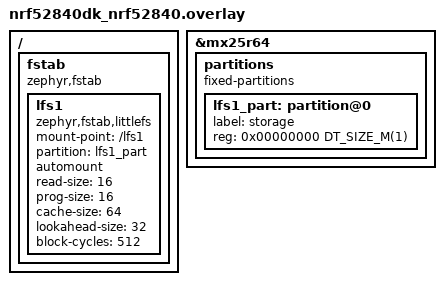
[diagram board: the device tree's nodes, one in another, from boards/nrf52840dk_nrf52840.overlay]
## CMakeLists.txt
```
# SPDX-FileCopyrightText: Copyright The Zephyr Project Contributors
# SPDX-FileCopyrightText: Copyright (c) 2026 Jeff Welder
# SPDX-License-Identifier: Apache-2.0

cmake_minimum_required(VERSION 3.20.0)
find_package(Zephyr REQUIRED HINTS $ENV{ZEPHYR_BASE})
project(smp_bt_client)

target_sources(app PRIVATE src/main.c)

# The image management client headers reach into <bootutil/image.h>, and the sample builds
# an MCUboot image header of its own, so the bootutil include path is needed here.
zephyr_library_link_libraries(MCUBOOT_BOOTUTIL)
```

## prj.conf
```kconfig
CONFIG_LOG=y
CONFIG_MAIN_STACK_SIZE=4096

# Bluetooth central with a GATT client, which is what the SMP client transport drives.
CONFIG_BT=y
CONFIG_BT_CENTRAL=y
CONFIG_BT_GATT_CLIENT=y
CONFIG_BT_DEVICE_NAME="SMP Client"

# Allow for large Bluetooth data packets, matching what smp_svr asks for in its bt.conf.
CONFIG_BT_L2CAP_TX_MTU=498
CONFIG_BT_BUF_ACL_RX_SIZE=502
CONFIG_BT_BUF_ACL_TX_SIZE=251
CONFIG_BT_CTLR_DATA_LENGTH_MAX=251

# None of the above buys anything until the ATT MTU itself is negotiated up from its
# default of 23, and only the central can ask for that: a peer running smp_svr has no GATT
# client of its own to initiate the exchange. Without this the transport spends the whole
# session writing 20 byte fragments.
CONFIG_BT_GATT_AUTO_UPDATE_MTU=y

# The client transport keeps up to MCUMGR_TRANSPORT_BT_CLIENT_TX_CREDITS write fragments in
# flight and needs an ATT buffer for each of them, with headroom left for everything else
# that shares the link.
CONFIG_BT_ATT_TX_COUNT=4

# MCUmgr SMP client over the Bluetooth central transport.
CONFIG_NET_BUF=y
CONFIG_ZCBOR=y
CONFIG_CRC=y
CONFIG_MCUMGR=y
CONFIG_SMP_CLIENT=y
CONFIG_MCUMGR_TRANSPORT_BT_CLIENT=y

# The image upload client sizes every upload frame from this without consulting the
# transport MTU, so it must not exceed the peer's own MCUMGR_TRANSPORT_NETBUF_SIZE, which
# is 2475 in the smp_svr sample.
CONFIG_MCUMGR_TRANSPORT_NETBUF_SIZE=2048

CONFIG_MCUMGR_GRP_IMG_CLIENT=y
CONFIG_MCUMGR_GRP_OS_CLIENT=y

# The image management client headers pull in <bootutil/image.h>, and the sample writes an
# MCUboot image header into the placeholder image it creates.
CONFIG_MCUBOOT_BOOTUTIL_LIB=y

# The image to upload is read from a littlefs file system.
CONFIG_FLASH=y
CONFIG_FLASH_MAP=y
CONFIG_FILE_SYSTEM=y
CONFIG_FILE_SYSTEM_LITTLEFS=y
```

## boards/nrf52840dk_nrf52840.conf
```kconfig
# The littlefs mount point is on the external QSPI flash.
CONFIG_MPU_ALLOW_FLASH_WRITE=y

# littlefs derives its block size from the flash page layout, and the default QSPI page
# size of 64 KiB would leave the 1 MiB partition with too few blocks to be usable.
CONFIG_NORDIC_QSPI_NOR_FLASH_LAYOUT_PAGE_SIZE=4096
```

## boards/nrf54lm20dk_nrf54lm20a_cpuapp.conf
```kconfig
# The littlefs mount point is on the external SPI flash rather than on a QSPI one.
CONFIG_SPI=y
CONFIG_SPI_NOR=y

# The devicetree node carries a JESD216 basic flash parameters table, so read the flash
# parameters from there instead of synthesising a minimal fixed configuration.
CONFIG_SPI_NOR_SFDP_DEVICETREE=y

# littlefs derives its block size from the flash page layout, and the driver's default
# page size of 64 KiB would leave the 1 MiB partition with too few blocks to be usable.
CONFIG_SPI_NOR_FLASH_LAYOUT_PAGE_SIZE=4096
```

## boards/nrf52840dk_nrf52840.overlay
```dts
/*
 * SPDX-FileCopyrightText: Copyright The Zephyr Project Contributors
 * SPDX-FileCopyrightText: Copyright (c) 2026 Jeff Welder
 *
 * SPDX-License-Identifier: Apache-2.0
 */

#include <zephyr/dt-bindings/dt-util.h>

/* The image to upload lives on the external QSPI flash, not in the internal one. */
/delete-node/ &storage_partition;

/ {
	fstab {
		compatible = "zephyr,fstab";

		lfs1: lfs1 {
			compatible = "zephyr,fstab,littlefs";
			mount-point = "/lfs1";
			partition = <&lfs1_part>;
			automount;
			read-size = <16>;
			prog-size = <16>;
			cache-size = <64>;
			lookahead-size = <32>;
			block-cycles = <512>;
		};
	};
};

&mx25r64 {
	partitions {
		compatible = "fixed-partitions";
		#address-cells = <1>;
		#size-cells = <1>;

		lfs1_part: partition@0 {
			label = "storage";
			reg = <0x00000000 DT_SIZE_M(1)>;
		};
	};
};
```

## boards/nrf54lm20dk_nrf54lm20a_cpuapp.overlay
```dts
/*
 * SPDX-FileCopyrightText: Copyright The Zephyr Project Contributors
 * SPDX-FileCopyrightText: Copyright (c) 2026 Jeff Welder
 *
 * SPDX-License-Identifier: Apache-2.0
 */

#include <zephyr/dt-bindings/dt-util.h>

/* The image to upload lives on the external SPI flash, not in the internal one. */
/delete-node/ &storage_partition;

/ {
	fstab {
		compatible = "zephyr,fstab";

		lfs1: lfs1 {
			compatible = "zephyr,fstab,littlefs";
			mount-point = "/lfs1";
			partition = <&lfs1_part>;
			automount;
			read-size = <16>;
			prog-size = <16>;
			cache-size = <64>;
			lookahead-size = <32>;
			block-cycles = <512>;
		};
	};
};

/*
 * The board carries the same MX25R64 as the nrf52840dk does, but on a plain SPI bus
 * rather than on QSPI, and left disabled by the board devicetree.
 */
&mx25r64 {
	status = "okay";

	partitions {
		compatible = "fixed-partitions";
		#address-cells = <1>;
		#size-cells = <1>;

		lfs1_part: partition@0 {
			label = "storage";
			reg = <0x00000000 DT_SIZE_M(1)>;
		};
	};
};
```

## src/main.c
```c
/*
 * SPDX-FileCopyrightText: Copyright The Zephyr Project Contributors
 * SPDX-FileCopyrightText: Copyright (c) 2026 Jeff Welder
 *
 * SPDX-License-Identifier: Apache-2.0
 */

/*
 * Uploads a firmware image to a Bluetooth peer that runs the SMP service, with this board
 * in the central role. The image is read from a littlefs file system on the board's
 * external QSPI flash, so nothing about it is baked into this binary.
 */

#include <errno.h>
#include <stdint.h>
#include <string.h>

#include <zephyr/bluetooth/bluetooth.h>
#include <zephyr/bluetooth/conn.h>
#include <zephyr/bluetooth/hci.h>
#include <zephyr/fs/fs.h>
#include <zephyr/kernel.h>
#include <zephyr/logging/log.h>
#include <zephyr/mgmt/mcumgr/grp/img_mgmt/img_mgmt_client.h>
#include <zephyr/mgmt/mcumgr/grp/os_mgmt/os_mgmt_client.h>
#include <zephyr/mgmt/mcumgr/smp/smp_client.h>
#include <zephyr/mgmt/mcumgr/transport/smp.h>
#include <zephyr/mgmt/mcumgr/transport/smp_bt.h>
#include <zephyr/mgmt/mcumgr/transport/smp_bt_client.h>
#include <zephyr/sys/atomic.h>

#include <bootutil/image.h>

LOG_MODULE_REGISTER(smp_bt_client_sample, LOG_LEVEL_INF);

#define AUTOMOUNT_NODE DT_NODELABEL(lfs1)
#define MOUNT_POINT    DT_PROP(AUTOMOUNT_NODE, mount_point)
#define IMAGE_PATH     MOUNT_POINT "/update.bin"

/* Placeholder image written when the file system holds no image yet. */
#define PLACEHOLDER_SIZE 4096U
/* How much of the file is handed to the image client per call. */
#define CHUNK_SIZE       1024U

#define ECHO_STRING "smp client"

BUILD_ASSERT(PLACEHOLDER_SIZE % CHUNK_SIZE == 0, "Placeholder must be a whole number of chunks");

static struct smp_client_object smp_client;
static struct img_mgmt_client img_client;
static struct os_mgmt_client os_client;
static uint8_t chunk[CHUNK_SIZE];

/*
 * The one reference this sample holds on the peer. Both the connected callback, on a
 * failed connection, and main, when it gives up waiting, want to release it, so whoever
 * swaps the pointer out first owns the release and the other side finds nothing to do.
 */
static atomic_ptr_t peer;
static K_SEM_DEFINE(peer_connected, 0, 1);

/* Matches the SMP service UUID that every Zephyr SMP Bluetooth server advertises. */
static bool adv_data_cb(struct bt_data *data, void *user_data)
{
	static const uint8_t smp_svc_uuid[] = {SMP_BT_SVC_UUID_VAL};
	bool *found = user_data;

	if (data->type == BT_DATA_UUID128_ALL && data->data_len == sizeof(smp_svc_uuid) &&
	    memcmp(data->data, smp_svc_uuid, sizeof(smp_svc_uuid)) == 0) {
		*found = true;
		return false;
	}

	return true;
}

static void scan_cb(const bt_addr_le_t *addr, int8_t rssi, uint8_t type, struct net_buf_simple *ad)
{
	char addr_str[BT_ADDR_LE_STR_LEN];
	bool found = false;
	int rc;

	if (type != BT_GAP_ADV_TYPE_ADV_IND) {
		return;
	}

	bt_data_parse(ad, adv_data_cb, &found);
	if (!found) {
		return;
	}

	bt_addr_le_to_str(addr, addr_str, sizeof(addr_str));
	LOG_INF("SMP server found at %s, RSSI %d", addr_str, rssi);

	rc = bt_le_scan_stop();
	if (rc == 0) {
		struct bt_conn *conn;

		rc = bt_conn_le_create(addr, BT_CONN_LE_CREATE_CONN, BT_LE_CONN_PARAM_DEFAULT,
				       &conn);
		if (rc == 0) {
			atomic_ptr_set(&peer, conn);
		}
	}

	if (rc != 0) {
		LOG_ERR("Failed to connect to the peer (err %d)", rc);
		k_sem_give(&peer_connected);
	}
}

static void connected(struct bt_conn *conn, uint8_t err)
{
	if (err != 0) {
		LOG_ERR("Connection failed (err 0x%02x)", err);
		/* Also reached when main cancels a connection it gave up waiting for; by
		 * then main has already taken the reference, and this finds nothing.
		 */
		if (atomic_ptr_cas(&peer, conn, NULL)) {
			bt_conn_unref(conn);
		}
	} else {
		LOG_INF("Connected");
	}

	k_sem_give(&peer_connected);
}

static void disconnected(struct bt_conn *conn, uint8_t reason)
{
	LOG_INF("Disconnected (reason 0x%02x)", reason);
}

BT_CONN_CB_DEFINE(conn_callbacks) = {
	.connected = connected,
	.disconnected = disconnected,
};

/*
 * Writes a zero filled image carrying nothing but a valid MCUboot image header, so that
 * the sample has something to upload out of the box: a peer running img_mgmt rejects the
 * first upload frame outright unless it starts with the MCUboot magic.
 */
static int placeholder_write(void)
{
	const struct image_header hdr = {
		.ih_magic = IMAGE_MAGIC,
		.ih_hdr_size = sizeof(struct image_header),
		.ih_img_size = PLACEHOLDER_SIZE - sizeof(struct image_header),
		.ih_ver = {.iv_revision = 1},
	};
	struct fs_file_t file;
	size_t off;
	int rc;

	memset(chunk, 0, sizeof(chunk));
	memcpy(chunk, &hdr, sizeof(hdr));

	fs_file_t_init(&file);
	rc = fs_open(&file, IMAGE_PATH, FS_O_CREATE | FS_O_WRITE);
	if (rc != 0) {
		return rc;
	}

	for (off = 0; off < PLACEHOLDER_SIZE; off += CHUNK_SIZE) {
		rc = fs_write(&file, chunk, CHUNK_SIZE);
		if (rc < 0) {
			break;
		}
		/* A short write means the file system is full, which leaves a truncated
		 * image behind; report it rather than upload something incomplete.
		 */
		if (rc != (int)CHUNK_SIZE) {
			rc = -ENOSPC;
			break;
		}
		/* Only the first chunk carries the header. */
		memset(chunk, 0, sizeof(hdr));
	}

	(void)fs_close(&file);
	return (rc < 0) ? rc : 0;
}

static int image_upload(size_t image_size)
{
	struct mcumgr_image_upload res;
	struct fs_file_t file;
	size_t sent = 0;
	int read_len;
	int rc;

	fs_file_t_init(&file);
	rc = fs_open(&file, IMAGE_PATH, FS_O_READ);
	if (rc != 0) {
		LOG_ERR("Failed to open %s (err %d)", IMAGE_PATH, rc);
		return rc;
	}

	/* Image 0, and no image hash, which also means that no upload can be resumed. */
	rc = img_mgmt_client_upload_init(&img_client, image_size, 0, NULL);
	if (rc != 0) {
		LOG_ERR("Failed to start the upload (err %d)", rc);
		goto out;
	}

	while (sent < image_size) {
		size_t offset = sent;

		/*
		 * The peer, not the file position, decides where the next frame starts:
		 * it answers every frame with the offset it expects next, and the image
		 * client puts that offset in the frame it sends. Seeking to it keeps the
		 * bytes and the offset they are labelled with in agreement. Reading on
		 * from wherever the file happened to be left would silently send the
		 * wrong bytes for the offset whenever the peer asks to resume anywhere
		 * other than exactly where this side stopped.
		 */
		rc = fs_seek(&file, offset, FS_SEEK_SET);
		if (rc != 0) {
			LOG_ERR("Failed to seek %s to %zu (err %d)", IMAGE_PATH, offset, rc);
			goto out;
		}

		read_len = fs_read(&file, chunk, sizeof(chunk));
		if (read_len <= 0) {
			LOG_ERR("Failed to read %s (err %d)", IMAGE_PATH, read_len);
			rc = (read_len == 0) ? -EIO : read_len;
			goto out;
		}

		rc = img_mgmt_client_upload(&img_client, chunk, read_len, &res);
		if (rc != 0) {
			LOG_ERR("Upload failed at offset %zu (err %d)", offset, rc);
			goto out;
		}

		sent = res.image_upload_offset;

		/* A peer that never advances would otherwise spin here forever. */
		if (sent <= offset) {
			LOG_ERR("Peer did not advance past offset %zu", offset);
			rc = -EIO;
			goto out;
		}

		LOG_INF("Uploaded %zu/%zu bytes", sent, image_size);
	}

out:
	(void)fs_close(&file);
	return rc;
}

int main(void)
{
	struct fs_statvfs vfs;
	struct bt_conn *conn;
	struct fs_dirent entry;
	int rc;

	LOG_INF("MCUmgr SMP client Bluetooth sample");

	/* fs_stat() reports -ENOENT both for a file that is not there and for a mount
	 * point that is not there, and the two want completely different fixes, so rule
	 * the second one out before reading anything into the first.
	 */
	rc = fs_statvfs(MOUNT_POINT, &vfs);
	if (rc != 0) {
		LOG_ERR("Nothing is mounted at %s (err %d); check the board's "
			"zephyr,fstab,littlefs entry",
			MOUNT_POINT, rc);
		return rc;
	}

	rc = fs_stat(IMAGE_PATH, &entry);
	if (rc == -ENOENT) {
		LOG_INF("No %s yet, writing a placeholder image", IMAGE_PATH);
		rc = placeholder_write();
		if (rc == 0) {
			rc = fs_stat(IMAGE_PATH, &entry);
		}
	}

	if (rc != 0) {
		LOG_ERR("Failed to access %s (err %d)", IMAGE_PATH, rc);
		return rc;
	}

	/* An upload of nothing at all would otherwise run to completion without a single
	 * frame reaching the peer, and report success.
	 */
	if (entry.size < sizeof(struct image_header)) {
		LOG_ERR("%s is %zu bytes, too small to be an image", IMAGE_PATH, entry.size);
		return -EINVAL;
	}
	LOG_INF("Image %s is %zu bytes", IMAGE_PATH, entry.size);

	rc = bt_enable(NULL);
	if (rc != 0) {
		LOG_ERR("Bluetooth init failed (err %d)", rc);
		return rc;
	}

	rc = bt_le_scan_start(BT_LE_SCAN_PASSIVE, scan_cb);
	if (rc != 0) {
		LOG_ERR("Failed to start scanning (err %d)", rc);
		return rc;
	}
	LOG_INF("Scanning for a peer that advertises the SMP service");

	rc = k_sem_take(&peer_connected, K_SECONDS(30));
	conn = (rc == 0) ? atomic_ptr_get(&peer) : NULL;
	if (conn == NULL) {
		/* The scan callback is still armed unless it stopped the scan itself,
		 * and nothing is waiting on it any more. Left running it would connect
		 * to a peer that turns up later with nobody to drive the link, holding
		 * it open and stopping the peer from advertising to anyone else.
		 */
		(void)bt_le_scan_stop();
		LOG_ERR("No SMP server to connect to");

		conn = atomic_ptr_set(&peer, NULL);
		if (conn != NULL) {
			/* A connection that was still being established when the wait
			 * gave up. Cancel it rather than leave the reference behind.
			 */
			(void)bt_conn_disconnect(conn, BT_HCI_ERR_REMOTE_USER_TERM_CONN);
			bt_conn_unref(conn);
		}

		return -ENOTCONN;
	}

	/* Attaching blocks until the peer's SMP service has been discovered and subscribed
	 * to, so it has to run here rather than on a work queue or a Bluetooth callback.
	 */
	rc = smp_bt_client_attach(conn, K_SECONDS(10));
	if (rc != 0) {
		LOG_ERR("Failed to attach the transport (err %d)", rc);
		goto disconnect;
	}
	LOG_INF("Transport attached to the peer's SMP service");

	rc = smp_client_object_init(&smp_client, SMP_BLUETOOTH_CLIENT_TRANSPORT);
	if (rc != 0) {
		LOG_ERR("Failed to initialise the SMP client (err %d)", rc);
		goto detach;
	}

	os_mgmt_client_init(&os_client, &smp_client);
	rc = os_mgmt_client_echo(&os_client, ECHO_STRING, sizeof(ECHO_STRING) - 1);
	if (rc != 0) {
		LOG_ERR("Echo command failed (err %d)", rc);
		goto detach;
	}
	LOG_INF("Peer answered the echo command");

	/* No image list buffer: the sample uploads, and never reads the peer's image state. */
	img_mgmt_client_init(&img_client, &smp_client, 0, NULL);
	rc = image_upload(entry.size);
	if (rc == 0) {
		LOG_INF("Image written to the peer's secondary slot");
	}

detach:
	smp_bt_client_detach();
disconnect:
	conn = atomic_ptr_set(&peer, NULL);
	if (conn != NULL) {
		(void)bt_conn_disconnect(conn, BT_HCI_ERR_REMOTE_USER_TERM_CONN);
		bt_conn_unref(conn);
	}

	return rc;
}
```
